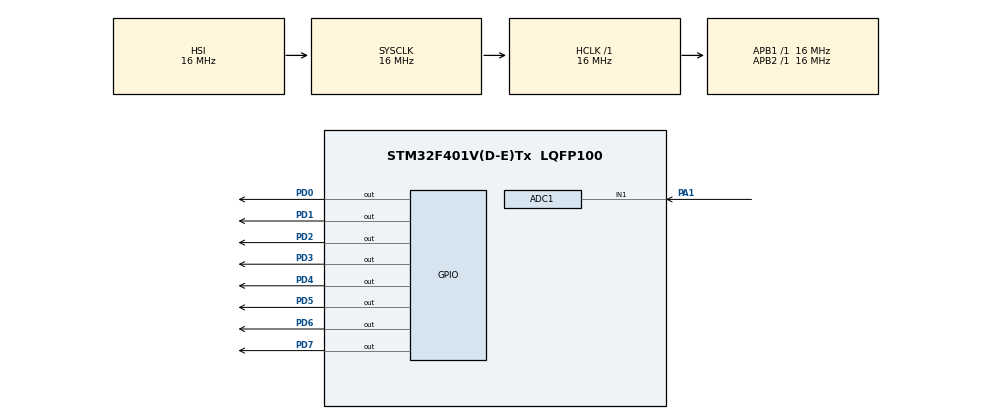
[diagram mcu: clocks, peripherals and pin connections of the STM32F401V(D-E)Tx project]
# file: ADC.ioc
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ADC1.Channel-0\#ChannelRegularConversion=ADC_CHANNEL_1
ADC1.ClockPrescaler=ADC_CLOCK_SYNC_PCLK_DIV4
ADC1.NbrOfConversionFlag=1
ADC1.Rank-0\#ChannelRegularConversion=1
ADC1.SamplingTime-0\#ChannelRegularConversion=ADC_SAMPLETIME_480CYCLES
ADC1.master=1
Mcu.Family=STM32F4
Mcu.Name=STM32F401V(D-E)Tx
Mcu.Package=LQFP100
NVIC.PriorityGroup=NVIC_PRIORITYGROUP_4
PA1.Signal=ADCx_IN1
PA13.Mode=Serial_Wire
PA13.Signal=SYS_JTMS-SWDIO
PA14.Mode=Serial_Wire
PA14.Signal=SYS_JTCK-SWCLK
PD0.Signal=GPIO_Output
PD1.Signal=GPIO_Output
PD2.Signal=GPIO_Output
PD3.Signal=GPIO_Output
PD4.Signal=GPIO_Output
PD5.Signal=GPIO_Output
PD6.Signal=GPIO_Output
PD7.Signal=GPIO_Output
PH0\ -\ OSC_IN.Mode=HSE-External-Oscillator
PH0\ -\ OSC_IN.Signal=RCC_OSC_IN
PH1\ -\ OSC_OUT.Mode=HSE-External-Oscillator
PH1\ -\ OSC_OUT.Signal=RCC_OSC_OUT
ProjectManager.HeapSize=0x200
ProjectManager.StackSize=0x400
ProjectManager.TargetToolchain=MDK-ARM V5.27
RCC.AHBFreq_Value=16000000
RCC.APB1Freq_Value=16000000
RCC.APB2Freq_Value=16000000
RCC.CortexFreq_Value=16000000
RCC.HSE_VALUE=25000000
RCC.HSI_VALUE=16000000
RCC.LSE_VALUE=32768
RCC.SYSCLKFreq_VALUE=16000000
RCC.VCOOutputFreq_Value=192000000
SH.ADCx_IN1.0=ADC1_IN1,IN1
board=custom

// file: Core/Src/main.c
/* USER CODE BEGIN Header */
/**
  ******************************************************************************
  * @file           : main.c
  * @brief          : Main program body
  ******************************************************************************
  * @attention
  *
  * <h2><center>&copy; Copyright (c) 2021 STMicroelectronics.
  * All rights reserved.</center></h2>
  *
  * This software component is licensed by ST under BSD 3-Clause license,
  * the "License"; You may not use this file except in compliance with the
  * License. You may obtain a copy of the License at:
  *                        opensource.org/licenses/BSD-3-Clause
  *
  ******************************************************************************
  */
/* USER CODE END Header */
#include "main.h"
#include "lcd_character.h"
#include "stdio.h"
#include "math.h"
#include "stdbool.h"

ADC_HandleTypeDef hadc1;

void reverse(char* str, int len)
{
    int i = 0, j = len - 1, temp;
    while (i < j)
    {
        temp = str[i];
        str[i] = str[j];
        str[j] = temp;
        i++;
        j--;
    }
}
int intToStr(int x, char str[], int d)
{
    int i = 0;
    while (x)
    {
        str[i++] = (x % 10) + '0';

        x = x / 10;
    }
    // If number of digits required is more, then
    // add 0s at the beginning
    while (i < d)
        str[i++] = '0';
    reverse(str, i);
    str[i] = '\0';
    return i;
}
void ftoa(float n, char* res, int afterpoint)
{
    // Extract integer part
    int ipart = (int)n;

    // Extract floating part
    float fpart = n - (float)ipart;

    // convert integer part to string
    int i = intToStr(ipart, res, 0);//0
    // check for display option after point
    if (afterpoint != 0)
    {
        res[i] = '.'; // add dot

        // Get the value of fraction part upto given no.
        // of points after dot. The third parameter
        // is needed to handle cases like 233.007

        fpart = fpart * pow(10, afterpoint);
        intToStr((int)fpart, res + i + 1, afterpoint);
    }
}

void SystemClock_Config(void);
static void MX_GPIO_Init(void);
static void MX_ADC1_Init(void);

/* USER CODE BEGIN 0 */
uint16_t value;
uint16_t vout;
float temp;
char lcdbuff[16];
/* USER CODE END 0 */

int main(void)
{

  /* MCU Configuration--------------------------------------------------------*/

  /* Reset of all peripherals, Initializes the Flash interface and the Systick. */
  HAL_Init();

  /* Configure the system clock */
  SystemClock_Config();

  /* Initialize all configured peripherals */
  MX_GPIO_Init();
  MX_ADC1_Init();
	lcd_init();

//	lcd_gotoxy(0,0);
// 	lcd_puts("WELCOME TO ADC");
  while (1)
  {
    HAL_ADC_Start(&hadc1);
    HAL_ADC_PollForConversion(&hadc1, HAL_MAX_DELAY);
    value = HAL_ADC_GetValue(&hadc1);
    HAL_ADC_Stop(&hadc1);

    vout = 3000 * value / 4096;
    temp = (float)vout / 10.0;

		lcd_gotoxy(0,0);
 		lcd_puts("vout=");
		intToStr(vout,lcdbuff,1);
		lcd_gotoxy(5,0);
		lcd_puts(lcdbuff);
		HAL_Delay(10);

		lcd_gotoxy(0,1);
 		lcd_puts("temp=");
		intToStr(temp,lcdbuff,0);
		lcd_gotoxy(5,5);
		lcd_puts(lcdbuff);
		HAL_Delay(10);

  }
  /* USER CODE END 3 */
}

void SystemClock_Config(void)
{
  RCC_OscInitTypeDef RCC_OscInitStruct = {0};
  RCC_ClkInitTypeDef RCC_ClkInitStruct = {0};

  /** Configure the main internal regulator output voltage
  */
  __HAL_RCC_PWR_CLK_ENABLE();
  __HAL_PWR_VOLTAGESCALING_CONFIG(PWR_REGULATOR_VOLTAGE_SCALE2);
  /** Initializes the RCC Oscillators according to the specified parameters
  * in the RCC_OscInitTypeDef structure.
  */
  RCC_OscInitStruct.OscillatorType = RCC_OSCILLATORTYPE_HSI;
  RCC_OscInitStruct.HSIState = RCC_HSI_ON;
  RCC_OscInitStruct.HSICalibrationValue = RCC_HSICALIBRATION_DEFAULT;
  RCC_OscInitStruct.PLL.PLLState = RCC_PLL_NONE;
  if (HAL_RCC_OscConfig(&RCC_OscInitStruct) != HAL_OK)
  {
    Error_Handler();
  }
  /** Initializes the CPU, AHB and APB buses clocks
  */
  RCC_ClkInitStruct.ClockType = RCC_CLOCKTYPE_HCLK|RCC_CLOCKTYPE_SYSCLK
                              |RCC_CLOCKTYPE_PCLK1|RCC_CLOCKTYPE_PCLK2;
  RCC_ClkInitStruct.SYSCLKSource = RCC_SYSCLKSOURCE_HSI;
  RCC_ClkInitStruct.AHBCLKDivider = RCC_SYSCLK_DIV1;
  RCC_ClkInitStruct.APB1CLKDivider = RCC_HCLK_DIV1;
  RCC_ClkInitStruct.APB2CLKDivider = RCC_HCLK_DIV1;

  if (HAL_RCC_ClockConfig(&RCC_ClkInitStruct, FLASH_LATENCY_0) != HAL_OK)
  {
    Error_Handler();
  }
}

static void MX_ADC1_Init(void)
{

  ADC_ChannelConfTypeDef sConfig = {0};

  /** Configure the global features of the ADC (Clock, Resolution, Data Alignment and number of conversion)
  */
  hadc1.Instance = ADC1;
  hadc1.Init.ClockPrescaler = ADC_CLOCK_SYNC_PCLK_DIV4;
  hadc1.Init.Resolution = ADC_RESOLUTION_12B;
  hadc1.Init.ScanConvMode = DISABLE;
  hadc1.Init.ContinuousConvMode = DISABLE;
  hadc1.Init.DiscontinuousConvMode = DISABLE;
  hadc1.Init.ExternalTrigConvEdge = ADC_EXTERNALTRIGCONVEDGE_NONE;
  hadc1.Init.ExternalTrigConv = ADC_SOFTWARE_START;
  hadc1.Init.DataAlign = ADC_DATAALIGN_RIGHT;
  hadc1.Init.NbrOfConversion = 1;
  hadc1.Init.DMAContinuousRequests = DISABLE;
  hadc1.Init.EOCSelection = ADC_EOC_SINGLE_CONV;
  if (HAL_ADC_Init(&hadc1) != HAL_OK)
  {
    Error_Handler();
  }
  /** Configure for the selected ADC regular channel its corresponding rank in the sequencer and its sample time.
  */
  sConfig.Channel = ADC_CHANNEL_1;
  sConfig.Rank = 1;
  sConfig.SamplingTime = ADC_SAMPLETIME_480CYCLES;
  if (HAL_ADC_ConfigChannel(&hadc1, &sConfig) != HAL_OK)
  {
    Error_Handler();
  }

}

static void MX_GPIO_Init(void)
{
  GPIO_InitTypeDef GPIO_InitStruct = {0};

  /* GPIO Ports Clock Enable */
  __HAL_RCC_GPIOH_CLK_ENABLE();
  __HAL_RCC_GPIOA_CLK_ENABLE();
  __HAL_RCC_GPIOD_CLK_ENABLE();

  /*Configure GPIO pin Output Level */
  HAL_GPIO_WritePin(GPIOD, GPIO_PIN_0|GPIO_PIN_1|GPIO_PIN_2|GPIO_PIN_3
                          |GPIO_PIN_4|GPIO_PIN_5|GPIO_PIN_6|GPIO_PIN_7, GPIO_PIN_RESET);

  /*Configure GPIO pins : PD0 PD1 PD2 PD3
                           PD4 PD5 PD6 PD7 */
  GPIO_InitStruct.Pin = GPIO_PIN_0|GPIO_PIN_1|GPIO_PIN_2|GPIO_PIN_3
                          |GPIO_PIN_4|GPIO_PIN_5|GPIO_PIN_6|GPIO_PIN_7;
  GPIO_InitStruct.Mode = GPIO_MODE_OUTPUT_PP;
  GPIO_InitStruct.Pull = GPIO_NOPULL;
  GPIO_InitStruct.Speed = GPIO_SPEED_FREQ_LOW;
  HAL_GPIO_Init(GPIOD, &GPIO_InitStruct);

}

void Error_Handler(void)
{
  __disable_irq();
  while (1)
  {
  }
}

/************************ (C) COPYRIGHT STMicroelectronics *****END OF FILE****/
